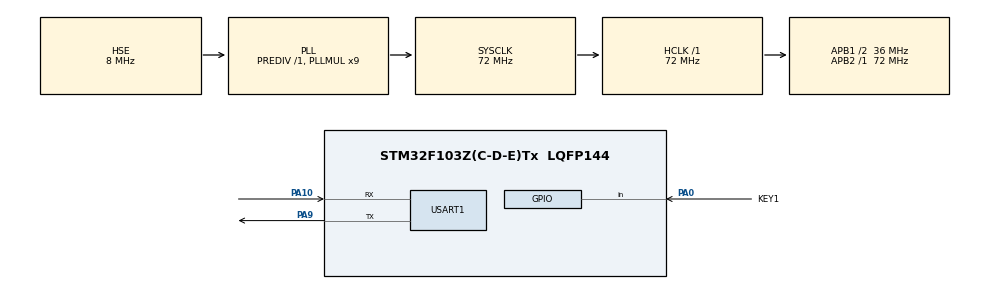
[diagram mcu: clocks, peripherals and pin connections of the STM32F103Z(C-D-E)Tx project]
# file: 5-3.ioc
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Mcu.Family=STM32F1
Mcu.Name=STM32F103Z(C-D-E)Tx
Mcu.Package=LQFP144
NVIC.PriorityGroup=NVIC_PRIORITYGROUP_4
NVIC.TIM1_UP_IRQn=true\:0\:0\:false\:false\:true\:true\:true\:true
NVIC.USART1_IRQn=true\:0\:0\:false\:false\:true\:true\:true\:true
OSC_IN.Mode=HSE-External-Oscillator
OSC_IN.Signal=RCC_OSC_IN
OSC_OUT.Mode=HSE-External-Oscillator
OSC_OUT.Signal=RCC_OSC_OUT
PA0-WKUP.GPIO_Label=KEY1
PA0-WKUP.GPIO_PuPd=GPIO_PULLDOWN
PA0-WKUP.Signal=GPIO_Input
PA10.Mode=Asynchronous
PA10.Signal=USART1_RX
PA13.Mode=Serial_Wire
PA13.Signal=SYS_JTMS-SWDIO
PA14.Mode=Serial_Wire
PA14.Signal=SYS_JTCK-SWCLK
PA9.Mode=Asynchronous
PA9.Signal=USART1_TX
PC14-OSC32_IN.Mode=LSE-External-Oscillator
PC14-OSC32_IN.Signal=RCC_OSC32_IN
PC15-OSC32_OUT.Mode=LSE-External-Oscillator
PC15-OSC32_OUT.Signal=RCC_OSC32_OUT
ProjectManager.HeapSize=0x200
ProjectManager.StackSize=0x400
ProjectManager.TargetToolchain=MDK-ARM V5.32
RCC.AHBFreq_Value=72000000
RCC.APB1CLKDivider=RCC_HCLK_DIV2
RCC.APB1Freq_Value=36000000
RCC.APB1TimFreq_Value=72000000
RCC.APB2Freq_Value=72000000
RCC.APB2TimFreq_Value=72000000
RCC.HCLKFreq_Value=72000000
RCC.PLLMUL=RCC_PLL_MUL9
RCC.PLLSourceVirtual=RCC_PLLSOURCE_HSE
RCC.SYSCLKFreq_VALUE=72000000
RCC.SYSCLKSource=RCC_SYSCLKSOURCE_PLLCLK
RCC.USBFreq_Value=72000000
TIM1.Period=999
TIM1.Prescaler=7199
USART1.VirtualMode=VM_ASYNC
VP_TIM1_VS_ClockSourceINT.Mode=Internal
board=custom

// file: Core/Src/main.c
/* USER CODE BEGIN Header */
/**
  ******************************************************************************
  * @file           : main.c
  * @brief          : Main program body
  ******************************************************************************
  * @attention
  *
  * Copyright (c) 2026 STMicroelectronics.
  * All rights reserved.
  *
  * This software is licensed under terms that can be found in the LICENSE file
  * in the root directory of this software component.
  * If no LICENSE file comes with this software, it is provided AS-IS.
  *
  ******************************************************************************
  */
/* USER CODE END Header */
#include "main.h"

/* USER CODE BEGIN Includes */
#include <stdio.h> // printf重定向
#include "Timer.h" // 秒表
#include "Key.h"    // 按键

/* USER CODE END Includes */

TIM_HandleTypeDef htim1;

UART_HandleTypeDef huart1;

void SystemClock_Config(void);
static void MX_GPIO_Init(void);
static void MX_TIM1_Init(void);
static void MX_USART1_UART_Init(void);

/* USER CODE BEGIN 0 */
int fputc(int ch, FILE *f) // print 重定向
{
    HAL_UART_Transmit(&huart1, (uint8_t*)&ch, 1, HAL_MAX_DELAY);
    return ch;
}
/* USER CODE END 0 */

int main(void)
{

  /* MCU Configuration--------------------------------------------------------*/

  /* Reset of all peripherals, Initializes the Flash interface and the Systick. */
  HAL_Init();

  /* Configure the system clock */
  SystemClock_Config();

  /* Initialize all configured peripherals */
  MX_GPIO_Init();
  MX_TIM1_Init();
  MX_USART1_UART_Init();

  /* USER CODE BEGIN 2 */
  printf("Press KEY1, start or stop the stopwatch \r\n"); // 按下 KEY1 暂停秒表

  /* USER CODE END 2 */

  /* Infinite loop */
  /* USER CODE BEGIN WHILE */
  while (1)
  {

    Key_Scan(); // 扫描按键
    if (Key1Flag)
    {
      Key1Flag = 0;
      SW_Statue = !SW_Statue; // 状态取反
      if (SW_Statue)
      {
        HAL_TIM_Base_Start_IT(&htim1);
        printf("Start\r\n");
      }
      else
      {
        HAL_TIM_Base_Stop_IT(&htim1);
        printf("Stop\r\n");
      }
    }

    // 秒表(自走)
    if (SW_Flag) // 打印标志位
    {
      SW_Flag = 0; // 清除打印标志位
      printf("Time : %02d : %02d : %02d \r\n", Clock.minute, Clock.second, Clock.ms100);
    }
    /* USER CODE END WHILE */

  }
}

void SystemClock_Config(void)
{
  RCC_OscInitTypeDef RCC_OscInitStruct = {0};
  RCC_ClkInitTypeDef RCC_ClkInitStruct = {0};

  /** Initializes the RCC Oscillators according to the specified parameters
  * in the RCC_OscInitTypeDef structure.
  */
  RCC_OscInitStruct.OscillatorType = RCC_OSCILLATORTYPE_HSE;
  RCC_OscInitStruct.HSEState = RCC_HSE_ON;
  RCC_OscInitStruct.HSEPredivValue = RCC_HSE_PREDIV_DIV1;
  RCC_OscInitStruct.HSIState = RCC_HSI_ON;
  RCC_OscInitStruct.PLL.PLLState = RCC_PLL_ON;
  RCC_OscInitStruct.PLL.PLLSource = RCC_PLLSOURCE_HSE;
  RCC_OscInitStruct.PLL.PLLMUL = RCC_PLL_MUL9;
  if (HAL_RCC_OscConfig(&RCC_OscInitStruct) != HAL_OK)
  {
    Error_Handler();
  }

  /** Initializes the CPU, AHB and APB buses clocks
  */
  RCC_ClkInitStruct.ClockType = RCC_CLOCKTYPE_HCLK|RCC_CLOCKTYPE_SYSCLK
                              |RCC_CLOCKTYPE_PCLK1|RCC_CLOCKTYPE_PCLK2;
  RCC_ClkInitStruct.SYSCLKSource = RCC_SYSCLKSOURCE_PLLCLK;
  RCC_ClkInitStruct.AHBCLKDivider = RCC_SYSCLK_DIV1;
  RCC_ClkInitStruct.APB1CLKDivider = RCC_HCLK_DIV2;
  RCC_ClkInitStruct.APB2CLKDivider = RCC_HCLK_DIV1;

  if (HAL_RCC_ClockConfig(&RCC_ClkInitStruct, FLASH_LATENCY_2) != HAL_OK)
  {
    Error_Handler();
  }
}

static void MX_TIM1_Init(void)
{

  TIM_ClockConfigTypeDef sClockSourceConfig = {0};
  TIM_MasterConfigTypeDef sMasterConfig = {0};

  htim1.Instance = TIM1;
  htim1.Init.Prescaler = 7199;
  htim1.Init.CounterMode = TIM_COUNTERMODE_UP;
  htim1.Init.Period = 999;
  htim1.Init.ClockDivision = TIM_CLOCKDIVISION_DIV1;
  htim1.Init.RepetitionCounter = 0;
  htim1.Init.AutoReloadPreload = TIM_AUTORELOAD_PRELOAD_DISABLE;
  if (HAL_TIM_Base_Init(&htim1) != HAL_OK)
  {
    Error_Handler();
  }
  sClockSourceConfig.ClockSource = TIM_CLOCKSOURCE_INTERNAL;
  if (HAL_TIM_ConfigClockSource(&htim1, &sClockSourceConfig) != HAL_OK)
  {
    Error_Handler();
  }
  sMasterConfig.MasterOutputTrigger = TIM_TRGO_RESET;
  sMasterConfig.MasterSlaveMode = TIM_MASTERSLAVEMODE_DISABLE;
  if (HAL_TIMEx_MasterConfigSynchronization(&htim1, &sMasterConfig) != HAL_OK)
  {
    Error_Handler();
  }
  /* USER CODE BEGIN TIM1_Init 2 */
  __HAL_TIM_CLEAR_FLAG(&htim1, TIM_FLAG_UPDATE); // 清除中断标志位
  // HAL_TIM_Base_Start_IT(&htim1); // 开启TIM1中断
  /* USER CODE END TIM1_Init 2 */

}

static void MX_USART1_UART_Init(void)
{

  huart1.Instance = USART1;
  huart1.Init.BaudRate = 115200;
  huart1.Init.WordLength = UART_WORDLENGTH_8B;
  huart1.Init.StopBits = UART_STOPBITS_1;
  huart1.Init.Parity = UART_PARITY_NONE;
  huart1.Init.Mode = UART_MODE_TX_RX;
  huart1.Init.HwFlowCtl = UART_HWCONTROL_NONE;
  huart1.Init.OverSampling = UART_OVERSAMPLING_16;
  if (HAL_UART_Init(&huart1) != HAL_OK)
  {
    Error_Handler();
  }

}

static void MX_GPIO_Init(void)
{
  GPIO_InitTypeDef GPIO_InitStruct = {0};

  /* GPIO Ports Clock Enable */
  __HAL_RCC_GPIOC_CLK_ENABLE();
  __HAL_RCC_GPIOA_CLK_ENABLE();

  /*Configure GPIO pin : KEY1_Pin */
  GPIO_InitStruct.Pin = KEY1_Pin;
  GPIO_InitStruct.Mode = GPIO_MODE_INPUT;
  GPIO_InitStruct.Pull = GPIO_PULLDOWN;
  HAL_GPIO_Init(KEY1_GPIO_Port, &GPIO_InitStruct);

}

void Error_Handler(void)
{
  __disable_irq();
  while (1)
  {
  }
}
